# F28x7x_can_regs register map
Vendor: Texas Instruments
Peripheral module from a debugger description file (folder C2000).
Address unit: 16 bits
Registers are 32-bit, read-only, no defined reset value unless marked. A register's access mark holds for its fields unless they carry their own. Offsets are as the file gives them; lines under a group give offsets from that group; [hi:lo] are bit positions; {n}, {i} and the like mark numbered series; 'fields as' and 'values as' point back to an identical list; <NAME> marks a mode.

## CAN_REGS — CAN Registers
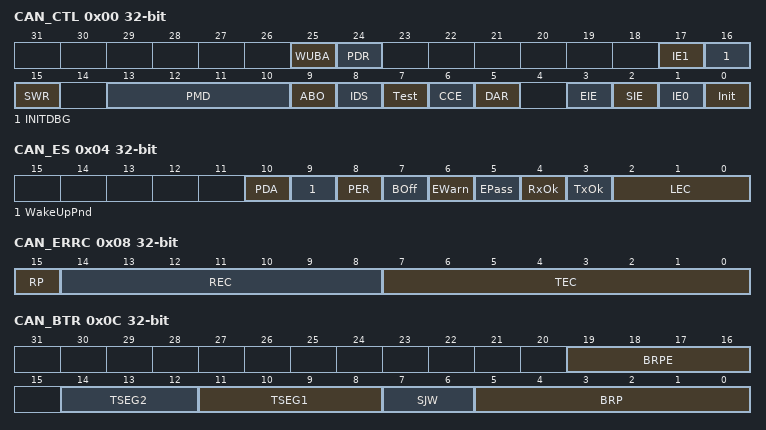
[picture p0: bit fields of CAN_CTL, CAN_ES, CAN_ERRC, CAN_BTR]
0x00 CAN_CTL access per field — CAN Control Register
  [25] WUBA rw — Wake Up on Bus Activity
  [24] PDR rw — Power Down Request Mode
  [17] IE1 rw — Interrupt line 1 Enable Disabled
  [16] INITDBG ro — Debug Mode Status
  [15] SWR rw — SW Reset Enable
  [13:10] PMD rw — Parity on/off
  [9] ABO rw — Auto-Bus-On Enable
  [8] IDS rw — Interruption Debug Support Enable
  [7] Test rw — Test Mode Enable
  [6] CCE rw — Configuration Change Enable
  [5] DAR rw — Disable Automatic Retransmission
  [3] EIE rw — Error Interrupt Enable Disabled
  [2] SIE rw — Status Change Interrupt Enable Disabled
  [1] IE0 rw — Interrupt line 0 Enable Disabled
  [0] Init rw — Initialization
0x04 CAN_ES — Error and Status Register
  [10] PDA — Power down mode acknowledge
  [9] WakeUpPnd — Wake Up Pending
  [8] PER — Parity Error Detected
  [7] BOff — Bus-Off State
  [6] EWarn — Warning State
  [5] EPass — Error Passive State
  [4] RxOk — Reception status
  [3] TxOk — Transmission status
  [2:0] LEC — Last Error Code
0x08 CAN_ERRC — Error Counter Register
  [15] RP — Receive Error Passive
  [14:8] REC — Receive Error Counter
  [7:0] TEC — Transmit Error Counter
0x0C CAN_BTR rw — Bit Timing Register
  [19:16] BRPE — Baud Rate Prescaler Extension
  [14:12] TSEG2 — Time segment
  [11:8] TSEG1 — Time segment
  [7:6] SJW — Synchronization Jump Width
  [5:0] BRP — Baud Rate Prescaler
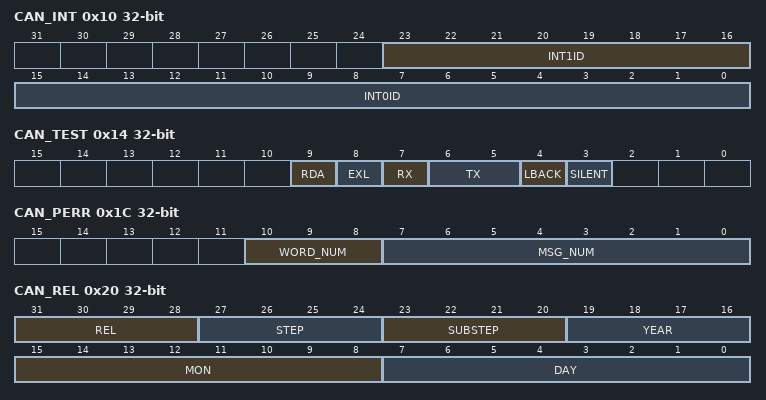
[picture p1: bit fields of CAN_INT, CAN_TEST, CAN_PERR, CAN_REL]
0x10 CAN_INT — Interrupt Register
  [23:16] INT1ID — Interrupt 1 Identifier
  [15:0] INT0ID — Interrupt Identifier
0x14 CAN_TEST access per field — Test Register
  [9] RDA rw — RAM Direct Access Enable:
  [8] EXL rw — External Loopback Mode
  [7] RX ro — CANRX Pin Status
  [6:5] TX rw — CANTX Pin Control
  [4] LBACK rw — Loopback Mode
  [3] SILENT rw — Silent Mode
0x1C CAN_PERR — CAN Parity Error Code Register
  [10:8] WORD_NUM — Word Number
  [7:0] MSG_NUM — Message Number
0x20 CAN_REL — CAN Core Release Register
  [31:28] REL — Release
  [27:24] STEP
  [23:20] SUBSTEP
  [19:16] YEAR
  [15:8] MON — Month
  [7:0] DAY
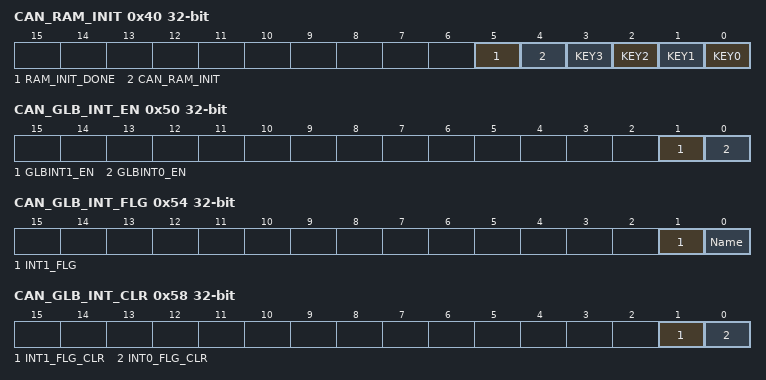
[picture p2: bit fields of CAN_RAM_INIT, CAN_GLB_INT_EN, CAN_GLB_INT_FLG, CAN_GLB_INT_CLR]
0x40 CAN_RAM_INIT access per field — CAN RAM Initialization Register
  [5] RAM_INIT_DONE ro — CAN RAM initialization complete
  [4] CAN_RAM_INIT rw — Initialize CAN Mailbox RAM
  [n] KEY{n} rw (n=0..3)
0x50 CAN_GLB_INT_EN rw — CAN Global Interrupt Enable Register
  [1] GLBINT1_EN — Global Interrupt Enable for CAN INT1
  [0] GLBINT0_EN — Global Interrupt Enable for CAN INT0
0x54 CAN_GLB_INT_FLG — CAN Global Interrupt Flag Register
  [1] INT1_FLG — Global Interrupt Flag for CAN INT1
  [0] Name — Global Interrupt Flag for CAN INT0
0x58 CAN_GLB_INT_CLR wo — CAN Global Interrupt Clear Register
  [1] INT1_FLG_CLR — Global Interrupt flag clear for CAN INT1
  [0] INT0_FLG_CLR — Global Interrupt flag clear for CAN INT0
0x80 CAN_ABOTR rw — Auto-Bus-On Time Register
  [31:0] ABO_Time — Auto-Bus-On Timer
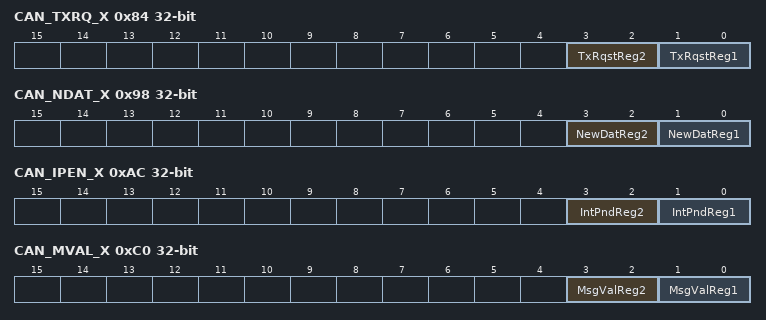
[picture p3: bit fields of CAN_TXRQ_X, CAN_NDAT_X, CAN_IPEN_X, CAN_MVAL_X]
0x84 CAN_TXRQ_X — CAN Transmission Request X Register
  [3:2] TxRqstReg2 — Transmit Request Register 2
  [1:0] TxRqstReg1 — Transmit Request Register 1
0x88 CAN_TXRQ_21 — CAN Transmission Request 2_1 Register
  [31:0] TxRqst — Transmission Request Bits
0x98 CAN_NDAT_X — CAN New Data X Register
  [3:2] NewDatReg2 — New Data Register 2
  [1:0] NewDatReg1 — New Data Register 1
0x9C CAN_NDAT_21 — CAN New Data 2_1 Register
  [31:0] NewDat — New Data Bits
0xAC CAN_IPEN_X — CAN Interrupt Pending X Register
  [3:2] IntPndReg2 — Interrupt Pending Register 2
  [1:0] IntPndReg1 — Interrupt Pending Register 1
0xB0 CAN_IPEN_21 — CAN Interrupt Pending 2_1 Register
  [31:0] IntPnd — Interrupt Pending
0xC0 CAN_MVAL_X — CAN Message Valid X Register
  [3:2] MsgValReg2 — Message Valid Register 2
  [1:0] MsgValReg1 — Message Valid Register 1
0xC4 CAN_MVAL_21 — CAN Message Valid 2_1 Register
  [31:0] MsgValReg — Message Valid Bits
0xD8 CAN_IP_MUX21 rw — CAN Interrupt Multiplexer 2_1 Register
  [31:0] IntMux — Interrupt Mux
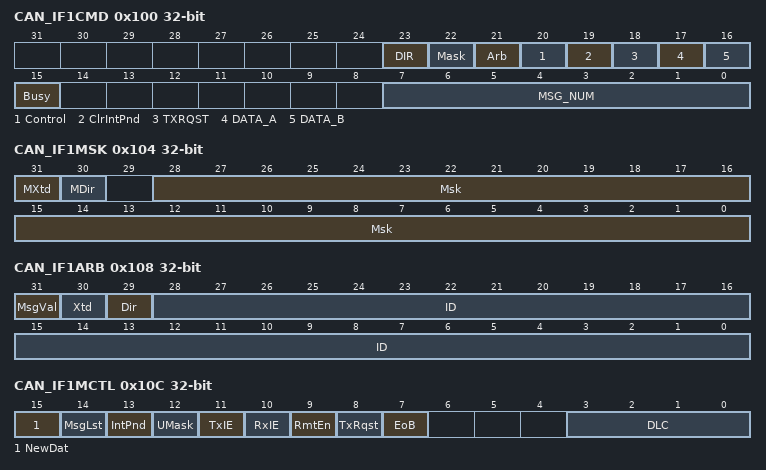
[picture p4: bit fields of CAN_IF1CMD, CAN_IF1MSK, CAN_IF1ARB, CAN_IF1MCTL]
0x100 CAN_IF1CMD access per field — IF1 Command Register
  [23] DIR rw — Write/Read Direction
  [22] Mask rw — Access Mask Bits
  [21] Arb rw — Access Arbitration Bits
  [20] Control rw — Access Control Bits
  [19] ClrIntPnd rw — Clear Interrupt Pending Bit
  [18] TXRQST rw — Access Transmission Request Bit
  [17] DATA_A rw — Access Data Bytes 0-3
  [16] DATA_B rw — Access Data Bytes 4-7
  [15] Busy ro — Busy Flag
  [7:0] MSG_NUM rw — Message Number
0x104 CAN_IF1MSK rw — IF1 Mask Register
  [31] MXtd — Mask Extended Identifier
  [30] MDir — Mask Message Direction
  [28:0] Msk — Identifier Mask
0x108 CAN_IF1ARB rw — IF1 Arbitration Register
  [31] MsgVal — Message Valid
  [30] Xtd — Extended Identifier
  [29] Dir — Message Direction
  [28:0] ID — `
0x10C CAN_IF1MCTL rw — IF1 Message Control Register
  [15] NewDat — New Data
  [14] MsgLst — Message Lost
  [13] IntPnd — Interrupt Pending
  [12] UMask — Use Acceptance Mask
  [11] TxIE — Transmit Interrupt Enable
  [10] RxIE — Receive Interrupt Enable
  [9] RmtEn — Remote Enable
  [8] TxRqst — Transmit Request
  [7] EoB — End of Block
  [3:0] DLC — Data length code
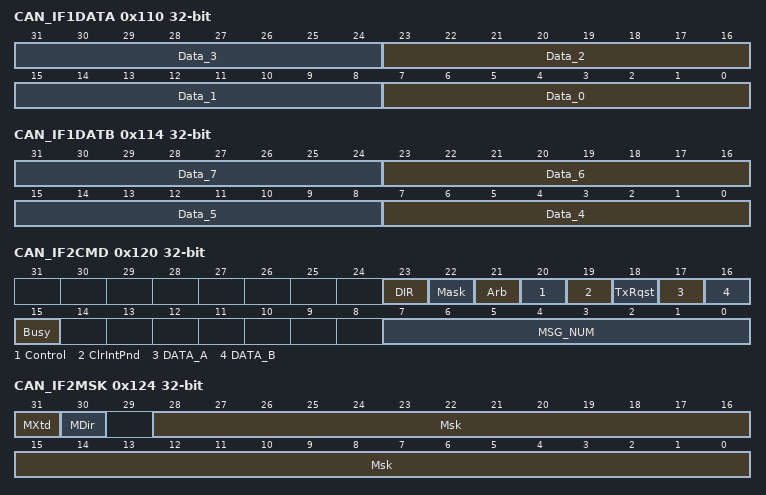
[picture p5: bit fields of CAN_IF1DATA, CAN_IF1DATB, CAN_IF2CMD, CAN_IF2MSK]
0x110 CAN_IF1DATA rw — IF1 Data A Register
  [8n+7:8n] Data_{n} (n=0..3) — Data Byte {n}
0x114 CAN_IF1DATB rw — IF1 Data B Register
  [8n-25:8n-32] Data_{n} (n=4..7) — Data Byte {n}
0x120 CAN_IF2CMD access per field — IF2 Command Register
  [23] DIR rw — Write/Read Direction
  [22] Mask rw — Access Mask Bits
  [21] Arb rw — Access Arbitration Bits
  [20] Control rw — Access Control Bits
  [19] ClrIntPnd rw — Clear Interrupt Pending Bit
  [18] TxRqst rw — Access Transmission Request Bit
  [17] DATA_A rw — Access Data Bytes 0-3
  [16] DATA_B rw — Access Data Bytes 4-7
  [15] Busy ro — Busy Flag
  [7:0] MSG_NUM rw — Message Number
0x124 CAN_IF2MSK rw — IF2 Mask Register
  fields as CAN_IF1MSK
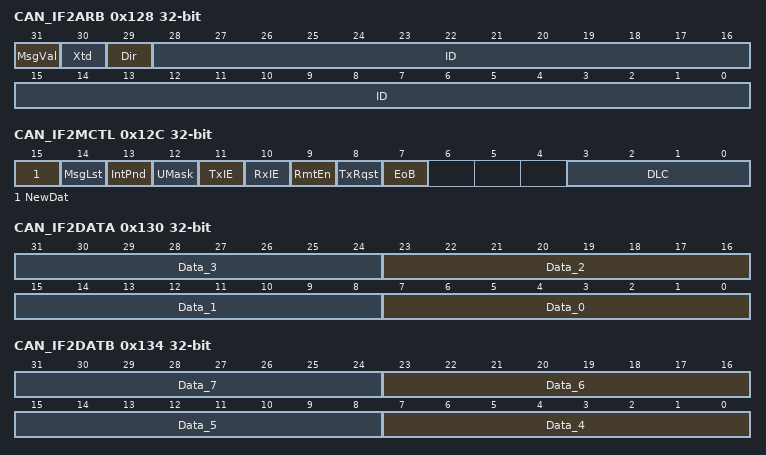
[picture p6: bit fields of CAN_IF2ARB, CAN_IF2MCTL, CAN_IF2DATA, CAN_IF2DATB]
0x128 CAN_IF2ARB rw — IF2 Arbitration Register
  [31] MsgVal — Message Valid
  [30] Xtd — Extended Identifier
  [29] Dir — Message Direction
  [28:0] ID — Message Identifier
0x12C CAN_IF2MCTL rw — IF2 Message Control Register
  fields as CAN_IF1MCTL
0x130 CAN_IF2DATA rw — IF2 Data A Register
  [8n+7:8n] Data_{n} (n=0..3) — Data Byte {n}
0x134 CAN_IF2DATB rw — IF2 Data B Register
  [8n-25:8n-32] Data_{n} (n=4..7) — Data Byte {n}
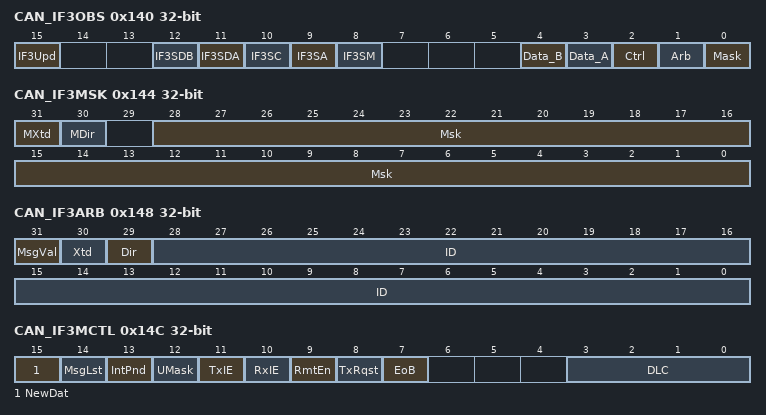
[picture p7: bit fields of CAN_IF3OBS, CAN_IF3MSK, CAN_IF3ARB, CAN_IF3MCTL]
0x140 CAN_IF3OBS access per field — IF3 Observation Register
  [15] IF3Upd ro — IF3 Update Data
  [12] IF3SDB ro — IF3 Status of Data B read access
  [11] IF3SDA ro — IF3 Status of Data A read access
  [10] IF3SC ro — IF3 Status of Control bits read access
  [9] IF3SA ro — IF3 Status of Arbitration data read access
  [8] IF3SM ro — IF3 Status of Mask data read access
  [4] Data_B rw — Data B read observation
  [3] Data_A rw — Data A read observation
  [2] Ctrl rw — Ctrl read observation
  [1] Arb rw — Arbitration data read observation
  [0] Mask rw — Mask data read observation
0x144 CAN_IF3MSK — IF3 Mask Register
  [31] MXtd — Mask Extended Identifier
  [30] MDir — Mask Message Direction
  [28:0] Msk — Mask
0x148 CAN_IF3ARB — IF3 Arbitration Register
  fields as CAN_IF2ARB
0x14C CAN_IF3MCTL — IF3 Message Control Register
  fields as CAN_IF1MCTL
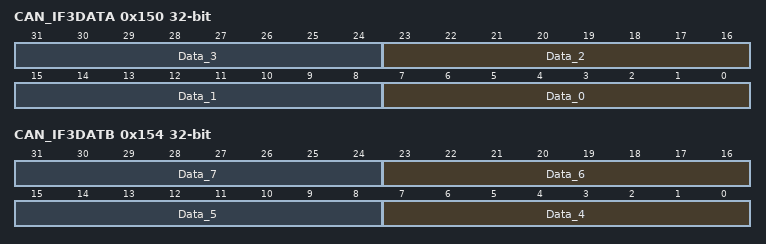
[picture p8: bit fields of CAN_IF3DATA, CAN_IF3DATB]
0x150 CAN_IF3DATA — IF3 Data A Register
  [8n+7:8n] Data_{n} (n=0..3) — Data Byte {n}
0x154 CAN_IF3DATB — IF3 Data B Register
  [8n-25:8n-32] Data_{n} (n=4..7) — Data Byte {n}
0x160 CAN_IF3UPD rw — IF3 Update Enable Register
  [31:0] IF3UpdEn — IF3 Update Enabled
